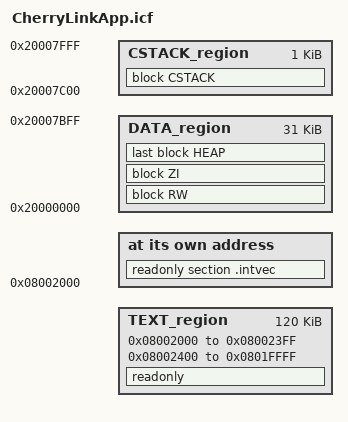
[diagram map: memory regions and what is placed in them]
/*###ICF### Section handled by SecondHandCoder ****/


/* Config */
define symbol stack_size                    = 0x00000400;
define symbol heap_size                     = 0x00000000;
define symbol m_vector_size                 = 0x00000400;
define symbol m_flash_start                 = 0x08000000;
define symbol m_boot_size                   = 0x00002000;
define symbol m_flash_size                  = 0x00020000;
define symbol m_vector_ram_size             = 0x00000000;

/* Flash */
define symbol m_vector_start                = m_flash_start+m_boot_size;
define symbol m_vector_end                  = m_vector_start+m_vector_size-1;

define symbol m_rom_start                   = m_flash_start+m_boot_size+m_vector_size;
define symbol m_rom_end                     = m_flash_start+m_flash_size-1;

/* Ram */
define symbol m_ram_start                   = 0x20000000;
define symbol m_ram_end                     = 0x20007FFF;


define memory mem with size = 4G;
define region TEXT_region                   = mem:[from m_vector_start to m_vector_end]
                                            | mem:[from m_rom_start to m_rom_end];
define region DATA_VEC_region               = mem:[from m_ram_start to m_ram_start+m_vector_ram_size-1];
define region DATA_region                   = mem:[from m_ram_start+m_vector_ram_size to m_ram_end-stack_size];
define region CSTACK_region                 = mem:[from m_ram_end-stack_size+1 to m_ram_end];

define block CSTACK                         with alignment = 8, size = stack_size   { };
define block HEAP                           with alignment = 8, size = heap_size    { };
define block RW                             { readwrite };
define block ZI                             { zi };

initialize manually                         { section .textrw };
initialize manually                         { section .bss };
initialize manually                         { section .data };
do not initialize                           { section .noinit, section .bss, section .data };


place at address mem: m_vector_start        { readonly section .intvec };
place in TEXT_region                        { readonly };
place in DATA_VEC_region                    { section m_interrupts_ram};
place in DATA_region                        { block RW };                    
place in DATA_region                        { block ZI };
place in DATA_region                        { last block HEAP };
place in CSTACK_region                      { block CSTACK };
